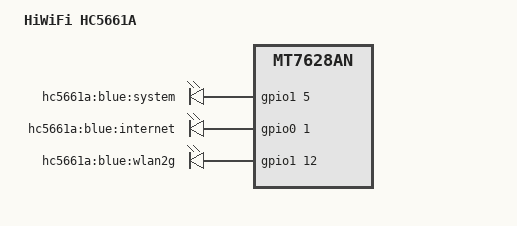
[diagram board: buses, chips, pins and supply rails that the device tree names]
// SPDX-License-Identifier: GPL-2.0-or-later OR MIT
/dts-v1/;

#include "HC5X61A.dtsi"

/ {
	compatible = "hiwifi,hc5661a", "mediatek,mt7628an-soc";
	model = "HiWiFi HC5661A";

	leds {
		compatible = "gpio-leds";

		led_system: system {
			label = "hc5661a:blue:system";
			gpios = <&gpio1 5 GPIO_ACTIVE_HIGH>;
		};

		internet {
			label = "hc5661a:blue:internet";
			gpios = <&gpio0 1 GPIO_ACTIVE_HIGH>;
		};

		wlan2g {
			label = "hc5661a:blue:wlan2g";
			gpios = <&gpio1 12 GPIO_ACTIVE_HIGH>;
			linux,default-trigger = "phy0tpt";
		};
	};
};

&pinctrl {
	state_default: pinctrl0 {
		gpio {
			ralink,group = "i2c", "refclk", "wled_an";
			ralink,function = "gpio";
		};
	};
};

&ehci {
	status = "disabled";
};

&ohci {
	status = "disabled";
};
